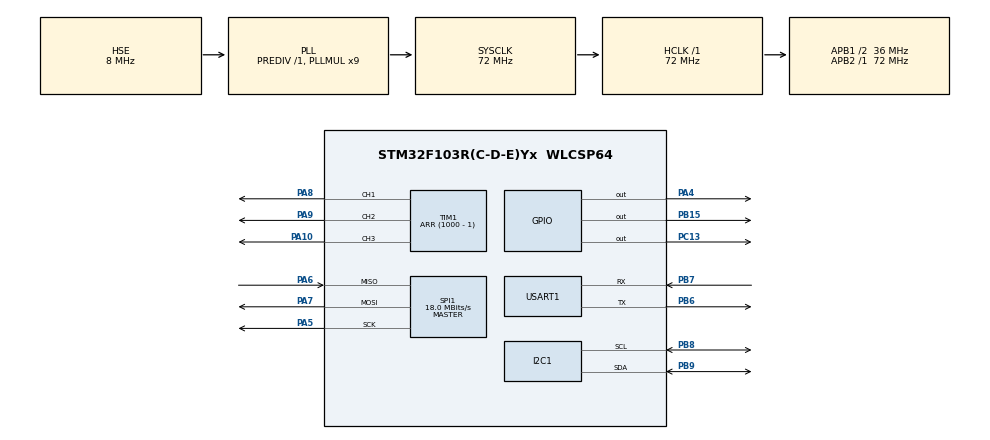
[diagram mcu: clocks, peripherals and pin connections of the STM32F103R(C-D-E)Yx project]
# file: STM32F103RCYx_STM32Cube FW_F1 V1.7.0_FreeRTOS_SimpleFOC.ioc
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FREERTOS.Tasks01=defaultTask,0,1024,StartDefaultTask,Default,NULL,Dynamic,NULL,NULL;myTask02,-3,1024,StartTask02,Default,NULL,Dynamic,NULL,NULL;myTask03,-3,1024,StartTask03,Default,NULL,Dynamic,NULL,NULL;myTask04,-3,1024,StartTask04,Default,NULL,Dynamic,NULL,NULL;myTask05,-3,1024,StartTask05,Default,NULL,Dynamic,NULL,NULL;myTask06,-3,1024,StartTask06,Default,NULL,Dynamic,NULL,NULL
FREERTOS.configMINIMAL_STACK_SIZE=1024
FREERTOS.configTOTAL_HEAP_SIZE=32768
Mcu.Family=STM32F1
Mcu.Name=STM32F103R(C-D-E)Yx
Mcu.Package=WLCSP64
NVIC.PriorityGroup=NVIC_PRIORITYGROUP_4
NVIC.TIM7_IRQn=true\:0\:0\:false\:false\:true\:false\:false\:true
NVIC.TimeBase=TIM7_IRQn
NVIC.TimeBaseIP=TIM7
NVIC.USART1_IRQn=true\:5\:0\:false\:false\:true\:true\:true\:true
PA10.Signal=S_TIM1_CH3
PA4.Signal=GPIO_Output
PA5.Mode=Full_Duplex_Master
PA5.Signal=SPI1_SCK
PA6.Mode=Full_Duplex_Master
PA6.Signal=SPI1_MISO
PA7.Mode=Full_Duplex_Master
PA7.Signal=SPI1_MOSI
PA8.Signal=S_TIM1_CH1
PA9.Signal=S_TIM1_CH2
PB15.Signal=GPIO_Output
PB6.Mode=Asynchronous
PB6.Signal=USART1_TX
PB7.Mode=Asynchronous
PB7.Signal=USART1_RX
PB8.Mode=I2C
PB8.Signal=I2C1_SCL
PB9.Mode=I2C
PB9.Signal=I2C1_SDA
PC13-TAMPER-RTC.Signal=GPIO_Output
PD0-OSC_IN.Mode=HSE-External-Oscillator
PD0-OSC_IN.Signal=RCC_OSC_IN
PD1-OSC_OUT.Mode=HSE-External-Oscillator
PD1-OSC_OUT.Signal=RCC_OSC_OUT
ProjectManager.HeapSize=0x200
ProjectManager.StackSize=0x400
ProjectManager.TargetToolchain=STM32CubeIDE
RCC.AHBFreq_Value=72000000
RCC.APB1CLKDivider=RCC_HCLK_DIV2
RCC.APB1Freq_Value=36000000
RCC.APB1TimFreq_Value=72000000
RCC.APB2Freq_Value=72000000
RCC.APB2TimFreq_Value=72000000
RCC.HCLKFreq_Value=72000000
RCC.PLLMUL=RCC_PLL_MUL9
RCC.PLLSourceVirtual=RCC_PLLSOURCE_HSE
RCC.SYSCLKFreq_VALUE=72000000
RCC.SYSCLKSource=RCC_SYSCLKSOURCE_PLLCLK
RCC.USBFreq_Value=72000000
SH.S_TIM1_CH1.0=TIM1_CH1,PWM Generation1 CH1
SH.S_TIM1_CH2.0=TIM1_CH2,PWM Generation2 CH2
SH.S_TIM1_CH3.0=TIM1_CH3,PWM Generation3 CH3
SPI1.BaudRatePrescaler=SPI_BAUDRATEPRESCALER_4
SPI1.CLKPhase=SPI_PHASE_2EDGE
SPI1.CalculateBaudRate=18.0 MBits/s
SPI1.Direction=SPI_DIRECTION_2LINES
SPI1.Mode=SPI_MODE_MASTER
SPI1.VirtualType=VM_MASTER
TIM1.AutoReloadPreload=TIM_AUTORELOAD_PRELOAD_ENABLE
TIM1.Channel-PWM\ Generation1\ CH1=TIM_CHANNEL_1
TIM1.Channel-PWM\ Generation2\ CH2=TIM_CHANNEL_2
TIM1.Channel-PWM\ Generation3\ CH3=TIM_CHANNEL_3
TIM1.CounterMode=TIM_COUNTERMODE_CENTERALIGNED3
TIM1.Period=(1000 - 1)
TIM1.Prescaler=(72000000 / 40000 / 1000 - 1)
USART1.VirtualMode=VM_ASYNC
VP_FREERTOS_VS_CMSIS_V1.Mode=CMSIS_V1
VP_SYS_VS_ND.Mode=No_Debug
VP_SYS_VS_tim7.Mode=TIM7
board=custom

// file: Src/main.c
/* USER CODE BEGIN Header */
/**
 ******************************************************************************
 * @file           : main.c
 * @brief          : Main program body
 ******************************************************************************
 * @attention
 *
 * <h2><center>&copy; Copyright (c) 2026 STMicroelectronics.
 * All rights reserved.</center></h2>
 *
 * This software component is licensed by ST under Ultimate Liberty license
 * SLA0044, the "License"; You may not use this file except in compliance with
 * the License. You may obtain a copy of the License at:
 *                             www.st.com/SLA0044
 *
 ******************************************************************************
 */
/* USER CODE END Header */

#include "main.h"

#include "cmsis_os.h"

/* USER CODE BEGIN Includes */
#include "Arduino.h"
#include "arduino_interface.h"
/* USER CODE END Includes */

I2C_HandleTypeDef hi2c1;

SPI_HandleTypeDef hspi1;

TIM_HandleTypeDef htim1;

UART_HandleTypeDef huart1;

osThreadId defaultTaskHandle;
osThreadId myTask02Handle;
osThreadId myTask03Handle;
osThreadId myTask04Handle;
osThreadId myTask05Handle;
osThreadId myTask06Handle;

void SystemClock_Config(void);
static void MX_GPIO_Init(void);
static void MX_I2C1_Init(void);
static void MX_SPI1_Init(void);
static void MX_TIM1_Init(void);
static void MX_USART1_UART_Init(void);
void StartDefaultTask(void const *argument);
void StartTask02(void const *argument);
void StartTask03(void const *argument);
void StartTask04(void const *argument);
void StartTask05(void const *argument);
void StartTask06(void const *argument);

int main(void) {

    /* MCU Configuration--------------------------------------------------------*/

    /* Reset of all peripherals, Initializes the Flash interface and the Systick. */
    HAL_Init();

    /* Configure the system clock */
    SystemClock_Config();

    /* Initialize all configured peripherals */
    MX_GPIO_Init();
    MX_I2C1_Init();
    MX_SPI1_Init();
    MX_TIM1_Init();
    MX_USART1_UART_Init();
    /* USER CODE BEGIN 2 */
    arduino_serial_init(&huart1);
    arduino_spi_init(&hspi1);
    arduino_tim_init(&htim1);
    arduino_hi2c_init(&hi2c1);
    /* USER CODE END 2 */

    /* Create the thread(s) */
    /* definition and creation of defaultTask */
    osThreadDef(defaultTask, StartDefaultTask, osPriorityNormal, 0, 1024);
    defaultTaskHandle = osThreadCreate(osThread(defaultTask), NULL);

    /* definition and creation of myTask02 */
    osThreadDef(myTask02, StartTask02, osPriorityIdle, 0, 1024);
    myTask02Handle = osThreadCreate(osThread(myTask02), NULL);

    /* definition and creation of myTask03 */
    osThreadDef(myTask03, StartTask03, osPriorityIdle, 0, 1024);
    myTask03Handle = osThreadCreate(osThread(myTask03), NULL);

    /* definition and creation of myTask04 */
    osThreadDef(myTask04, StartTask04, osPriorityIdle, 0, 1024);
    myTask04Handle = osThreadCreate(osThread(myTask04), NULL);

    /* definition and creation of myTask05 */
    osThreadDef(myTask05, StartTask05, osPriorityIdle, 0, 1024);
    myTask05Handle = osThreadCreate(osThread(myTask05), NULL);

    /* definition and creation of myTask06 */
    osThreadDef(myTask06, StartTask06, osPriorityIdle, 0, 1024);
    myTask06Handle = osThreadCreate(osThread(myTask06), NULL);

    /* Start scheduler */
    osKernelStart();

    /* We should never get here as control is now taken by the scheduler */

    /* Infinite loop */
    while (1) {

    }
}

void SystemClock_Config(void) {
    RCC_OscInitTypeDef RCC_OscInitStruct = {0};
    RCC_ClkInitTypeDef RCC_ClkInitStruct = {0};

    /** Initializes the CPU, AHB and APB busses clocks
     */
    RCC_OscInitStruct.OscillatorType = RCC_OSCILLATORTYPE_HSE;
    RCC_OscInitStruct.HSEState = RCC_HSE_ON;
    RCC_OscInitStruct.HSEPredivValue = RCC_HSE_PREDIV_DIV1;
    RCC_OscInitStruct.HSIState = RCC_HSI_ON;
    RCC_OscInitStruct.PLL.PLLState = RCC_PLL_ON;
    RCC_OscInitStruct.PLL.PLLSource = RCC_PLLSOURCE_HSE;
    RCC_OscInitStruct.PLL.PLLMUL = RCC_PLL_MUL9;
    if (HAL_RCC_OscConfig(&RCC_OscInitStruct) != HAL_OK) {
        Error_Handler();
    }
    /** Initializes the CPU, AHB and APB busses clocks
     */
    RCC_ClkInitStruct.ClockType = RCC_CLOCKTYPE_HCLK | RCC_CLOCKTYPE_SYSCLK | RCC_CLOCKTYPE_PCLK1 | RCC_CLOCKTYPE_PCLK2;
    RCC_ClkInitStruct.SYSCLKSource = RCC_SYSCLKSOURCE_PLLCLK;
    RCC_ClkInitStruct.AHBCLKDivider = RCC_SYSCLK_DIV1;
    RCC_ClkInitStruct.APB1CLKDivider = RCC_HCLK_DIV2;
    RCC_ClkInitStruct.APB2CLKDivider = RCC_HCLK_DIV1;

    if (HAL_RCC_ClockConfig(&RCC_ClkInitStruct, FLASH_LATENCY_2) != HAL_OK) {
        Error_Handler();
    }
}

static void MX_I2C1_Init(void) {

    hi2c1.Instance = I2C1;
    hi2c1.Init.ClockSpeed = 100000;
    hi2c1.Init.DutyCycle = I2C_DUTYCYCLE_2;
    hi2c1.Init.OwnAddress1 = 0;
    hi2c1.Init.AddressingMode = I2C_ADDRESSINGMODE_7BIT;
    hi2c1.Init.DualAddressMode = I2C_DUALADDRESS_DISABLE;
    hi2c1.Init.OwnAddress2 = 0;
    hi2c1.Init.GeneralCallMode = I2C_GENERALCALL_DISABLE;
    hi2c1.Init.NoStretchMode = I2C_NOSTRETCH_DISABLE;
    if (HAL_I2C_Init(&hi2c1) != HAL_OK) {
        Error_Handler();
    }
}

static void MX_SPI1_Init(void) {

    /* SPI1 parameter configuration*/
    hspi1.Instance = SPI1;
    hspi1.Init.Mode = SPI_MODE_MASTER;
    hspi1.Init.Direction = SPI_DIRECTION_2LINES;
    hspi1.Init.DataSize = SPI_DATASIZE_8BIT;
    hspi1.Init.CLKPolarity = SPI_POLARITY_LOW;
    hspi1.Init.CLKPhase = SPI_PHASE_2EDGE;
    hspi1.Init.NSS = SPI_NSS_SOFT;
    hspi1.Init.BaudRatePrescaler = SPI_BAUDRATEPRESCALER_4;
    hspi1.Init.FirstBit = SPI_FIRSTBIT_MSB;
    hspi1.Init.TIMode = SPI_TIMODE_DISABLE;
    hspi1.Init.CRCCalculation = SPI_CRCCALCULATION_DISABLE;
    hspi1.Init.CRCPolynomial = 10;
    if (HAL_SPI_Init(&hspi1) != HAL_OK) {
        Error_Handler();
    }
}

static void MX_TIM1_Init(void) {

    TIM_MasterConfigTypeDef sMasterConfig = {0};
    TIM_OC_InitTypeDef sConfigOC = {0};
    TIM_BreakDeadTimeConfigTypeDef sBreakDeadTimeConfig = {0};

    htim1.Instance = TIM1;
    htim1.Init.Prescaler = (72000000 / 40000 / 1000 - 1);
    htim1.Init.CounterMode = TIM_COUNTERMODE_CENTERALIGNED3;
    htim1.Init.Period = (1000 - 1);
    htim1.Init.ClockDivision = TIM_CLOCKDIVISION_DIV1;
    htim1.Init.RepetitionCounter = 0;
    htim1.Init.AutoReloadPreload = TIM_AUTORELOAD_PRELOAD_ENABLE;
    if (HAL_TIM_PWM_Init(&htim1) != HAL_OK) {
        Error_Handler();
    }
    sMasterConfig.MasterOutputTrigger = TIM_TRGO_RESET;
    sMasterConfig.MasterSlaveMode = TIM_MASTERSLAVEMODE_DISABLE;
    if (HAL_TIMEx_MasterConfigSynchronization(&htim1, &sMasterConfig) != HAL_OK) {
        Error_Handler();
    }
    sConfigOC.OCMode = TIM_OCMODE_PWM1;
    sConfigOC.Pulse = 0;
    sConfigOC.OCPolarity = TIM_OCPOLARITY_HIGH;
    sConfigOC.OCNPolarity = TIM_OCNPOLARITY_HIGH;
    sConfigOC.OCFastMode = TIM_OCFAST_DISABLE;
    sConfigOC.OCIdleState = TIM_OCIDLESTATE_RESET;
    sConfigOC.OCNIdleState = TIM_OCNIDLESTATE_RESET;
    if (HAL_TIM_PWM_ConfigChannel(&htim1, &sConfigOC, TIM_CHANNEL_1) != HAL_OK) {
        Error_Handler();
    }
    if (HAL_TIM_PWM_ConfigChannel(&htim1, &sConfigOC, TIM_CHANNEL_2) != HAL_OK) {
        Error_Handler();
    }
    if (HAL_TIM_PWM_ConfigChannel(&htim1, &sConfigOC, TIM_CHANNEL_3) != HAL_OK) {
        Error_Handler();
    }
    sBreakDeadTimeConfig.OffStateRunMode = TIM_OSSR_DISABLE;
    sBreakDeadTimeConfig.OffStateIDLEMode = TIM_OSSI_DISABLE;
    sBreakDeadTimeConfig.LockLevel = TIM_LOCKLEVEL_OFF;
    sBreakDeadTimeConfig.DeadTime = 0;
    sBreakDeadTimeConfig.BreakState = TIM_BREAK_DISABLE;
    sBreakDeadTimeConfig.BreakPolarity = TIM_BREAKPOLARITY_HIGH;
    sBreakDeadTimeConfig.AutomaticOutput = TIM_AUTOMATICOUTPUT_DISABLE;
    if (HAL_TIMEx_ConfigBreakDeadTime(&htim1, &sBreakDeadTimeConfig) != HAL_OK) {
        Error_Handler();
    }
    HAL_TIM_MspPostInit(&htim1);
}

static void MX_USART1_UART_Init(void) {

    huart1.Instance = USART1;
    huart1.Init.BaudRate = 115200;
    huart1.Init.WordLength = UART_WORDLENGTH_8B;
    huart1.Init.StopBits = UART_STOPBITS_1;
    huart1.Init.Parity = UART_PARITY_NONE;
    huart1.Init.Mode = UART_MODE_TX_RX;
    huart1.Init.HwFlowCtl = UART_HWCONTROL_NONE;
    huart1.Init.OverSampling = UART_OVERSAMPLING_16;
    if (HAL_UART_Init(&huart1) != HAL_OK) {
        Error_Handler();
    }
}

static void MX_GPIO_Init(void) {
    GPIO_InitTypeDef GPIO_InitStruct = {0};

    /* GPIO Ports Clock Enable */
    __HAL_RCC_GPIOB_CLK_ENABLE();
    __HAL_RCC_GPIOC_CLK_ENABLE();
    __HAL_RCC_GPIOA_CLK_ENABLE();
    __HAL_RCC_GPIOD_CLK_ENABLE();

    /*Configure GPIO pin Output Level */
    HAL_GPIO_WritePin(GPIOC, GPIO_PIN_13, GPIO_PIN_RESET);

    /*Configure GPIO pin Output Level */
    HAL_GPIO_WritePin(GPIOB, GPIO_PIN_15, GPIO_PIN_RESET);

    /*Configure GPIO pin Output Level */
    HAL_GPIO_WritePin(GPIOA, GPIO_PIN_4, GPIO_PIN_RESET);

    /*Configure GPIO pin : PC13 */
    GPIO_InitStruct.Pin = GPIO_PIN_13;
    GPIO_InitStruct.Mode = GPIO_MODE_OUTPUT_PP;
    GPIO_InitStruct.Pull = GPIO_NOPULL;
    GPIO_InitStruct.Speed = GPIO_SPEED_FREQ_LOW;
    HAL_GPIO_Init(GPIOC, &GPIO_InitStruct);

    /*Configure GPIO pin : PB15 */
    GPIO_InitStruct.Pin = GPIO_PIN_15;
    GPIO_InitStruct.Mode = GPIO_MODE_OUTPUT_PP;
    GPIO_InitStruct.Pull = GPIO_NOPULL;
    GPIO_InitStruct.Speed = GPIO_SPEED_FREQ_LOW;
    HAL_GPIO_Init(GPIOB, &GPIO_InitStruct);

    /*Configure GPIO pin : PA4 */
    GPIO_InitStruct.Pin = GPIO_PIN_4;
    GPIO_InitStruct.Mode = GPIO_MODE_OUTPUT_PP;
    GPIO_InitStruct.Pull = GPIO_NOPULL;
    GPIO_InitStruct.Speed = GPIO_SPEED_FREQ_LOW;
    HAL_GPIO_Init(GPIOA, &GPIO_InitStruct);
}

void StartDefaultTask(void const *argument) {
    for (;;) {
        osDelay(1);
    }
}

void StartTask02(void const *argument) {
    /* USER CODE BEGIN StartTask02 */
    /* Infinite loop */
    for (;;) {
        osDelay(200);
        HAL_GPIO_TogglePin(GPIOC, GPIO_PIN_13);
    }
    /* USER CODE END StartTask02 */
}

void StartTask03(void const *argument) {
    /* USER CODE BEGIN StartTask03 */
    setup();
    TickType_t lastWakeTime = osKernelSysTick();
    /* Infinite loop */
    for (;;) {
        osDelayUntil(&lastWakeTime, 1);
        loop();
    }
    /* USER CODE END StartTask03 */
}

void StartTask04(void const *argument) {
    for (;;) {
        osDelay(1);
    }
}

void StartTask05(void const *argument) {
    for (;;) {
        osDelay(1);
    }
}

void StartTask06(void const *argument) {
    for (;;) {
        osDelay(1);
    }
}

void HAL_TIM_PeriodElapsedCallback(TIM_HandleTypeDef *htim) {
    if (htim->Instance == TIM7) {
        HAL_IncTick();
    }
}

void Error_Handler(void) {
}

/************************ (C) COPYRIGHT STMicroelectronics *****END OF FILE****/
